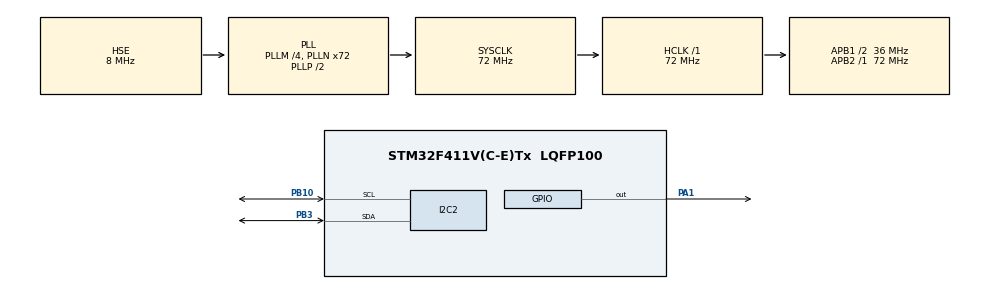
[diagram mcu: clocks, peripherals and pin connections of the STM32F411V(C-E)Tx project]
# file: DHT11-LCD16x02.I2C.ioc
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Mcu.Family=STM32F4
Mcu.Name=STM32F411V(C-E)Tx
Mcu.Package=LQFP100
NVIC.PriorityGroup=NVIC_PRIORITYGROUP_4
PA1.GPIO_PuPd=GPIO_PULLUP
PA1.Signal=GPIO_Output
PA13.Mode=Serial_Wire
PA13.Signal=SYS_JTMS-SWDIO
PA14.Mode=Serial_Wire
PA14.Signal=SYS_JTCK-SWCLK
PB10.Mode=I2C
PB10.Signal=I2C2_SCL
PB3.Mode=I2C
PB3.Signal=I2C2_SDA
PH0\ -\ OSC_IN.Mode=HSE-External-Oscillator
PH0\ -\ OSC_IN.Signal=RCC_OSC_IN
PH1\ -\ OSC_OUT.Mode=HSE-External-Oscillator
PH1\ -\ OSC_OUT.Signal=RCC_OSC_OUT
ProjectManager.HeapSize=0x200
ProjectManager.StackSize=0x400
ProjectManager.TargetToolchain=STM32CubeIDE
RCC.48MHZClocksFreq_Value=36000000
RCC.AHBFreq_Value=72000000
RCC.APB1CLKDivider=RCC_HCLK_DIV2
RCC.APB1Freq_Value=36000000
RCC.APB1TimFreq_Value=72000000
RCC.APB2Freq_Value=72000000
RCC.APB2TimFreq_Value=72000000
RCC.CortexFreq_Value=72000000
RCC.HCLKFreq_Value=72000000
RCC.HSE_VALUE=8000000
RCC.HSI_VALUE=16000000
RCC.LSE_VALUE=32768
RCC.PLLM=4
RCC.PLLN=72
RCC.PLLSourceVirtual=RCC_PLLSOURCE_HSE
RCC.SYSCLKFreq_VALUE=72000000
RCC.SYSCLKSource=RCC_SYSCLKSOURCE_PLLCLK
RCC.VCOOutputFreq_Value=144000000
TIM10.Period=0xffff-1
TIM10.Prescaler=72-1
VP_TIM10_VS_ClockSourceINT.Mode=Enable_Timer
board=custom

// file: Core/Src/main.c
/* USER CODE BEGIN Header */
/**
 ******************************************************************************
 * @file           : main.c
 * @brief          : Main program body
 ******************************************************************************
 * @attention
 *
 * Copyright (c) 2023 STMicroelectronics.
 * All rights reserved.
 *
 * This software is licensed under terms that can be found in the LICENSE file
 * in the root directory of this software component.
 * If no LICENSE file comes with this software, it is provided AS-IS.
 *
 ******************************************************************************
 */
/* USER CODE END Header */
#include "main.h"

/* USER CODE BEGIN Includes */
#include "lcd.h"
#include "stdio.h"
/* USER CODE END Includes */

/* USER CODE BEGIN PD */
#define DHT11_PORT_A GPIOA
#define DHT11_PIN_1 GPIO_PIN_1
/* USER CODE END PD */

I2C_HandleTypeDef hi2c2;

TIM_HandleTypeDef htim10;

/* USER CODE BEGIN PV */
uint8_t Rh_byte1, Rh_byte2, Temp_byte1, Temp_byte2;
uint16_t SUM, RH, TEMP;
float Temperature = 0;
float Humidity = 0;
uint8_t Presence = 0;
/* USER CODE END PV */

void SystemClock_Config(void);
static void MX_GPIO_Init(void);
static void MX_TIM10_Init(void);
static void MX_I2C2_Init(void);

/* USER CODE BEGIN 0 */
void delay_us(uint16_t us) {
	/* change your code here for the delay in microseconds */
	__HAL_TIM_SET_COUNTER(&htim10, 0);
	while ((__HAL_TIM_GET_COUNTER(&htim10)) < us)
		;
}

void Display_Temp(float Temp) {
	char str[20] = { 0 };
	lcd_put_cur(0, 7);
	sprintf(str, "%.2f", Temp);
	lcd_send_string(str);

}

void Display_Rh(float Rh) {
	char str[20] = { 0 };
	lcd_put_cur(1, 7);
	sprintf(str, "%.2f", Rh);
	lcd_send_string(str);

}

void Set_Pin_Output(GPIO_TypeDef *GPIOx, uint16_t GPIO_Pin) {
	GPIO_InitTypeDef GPIO_InitStruct = { 0 };
	GPIO_InitStruct.Pin = GPIO_Pin;
	GPIO_InitStruct.Mode = GPIO_MODE_OUTPUT_PP;
	GPIO_InitStruct.Speed = GPIO_SPEED_FREQ_LOW;
	HAL_GPIO_Init(GPIOx, &GPIO_InitStruct);
}
void Set_Pin_Input(GPIO_TypeDef *GPIOx, uint16_t GPIO_Pin) {
	GPIO_InitTypeDef GPIO_InitStruct = { 0 };
	GPIO_InitStruct.Pin = GPIO_Pin;
	GPIO_InitStruct.Mode = GPIO_MODE_INPUT;
	GPIO_InitStruct.Pull = GPIO_PULLUP;
	HAL_GPIO_Init(GPIOx, &GPIO_InitStruct);
}
void DHT11_Init() {
	Set_Pin_Output(GPIOA, GPIO_PIN_1); //set PA1 ouput to pull down in 18ms
	HAL_GPIO_WritePin(DHT11_PORT_A, DHT11_PIN_1, 0); //pull down in 18ms
	delay_us(18000); //18ms
	HAL_GPIO_WritePin(DHT11_PORT_A, DHT11_PIN_1, 1);
	delay_us(20); //pull wait
	Set_Pin_Input(DHT11_PORT_A, DHT11_PIN_1);
}
uint8_t DHT11_CheckRespone() {
	uint8_t Respone = 0;
	delay_us(40); //point middle low
	if (!HAL_GPIO_ReadPin(DHT11_PORT_A, DHT11_PIN_1)) {
		delay_us(80); //point middle high
		if (!HAL_GPIO_ReadPin(DHT11_PORT_A, DHT11_PIN_1))
			Respone = 1;
		else
			Respone = -1;
	}
		uint32_t timeout = 0;
		while (HAL_GPIO_ReadPin(DHT11_PORT_A, DHT11_PIN_1))
			if (timeout++ > 1160 * 4 * 2)
				break; //wait to go low

	return Respone;
}
uint8_t DHT11_ReadData() {

	uint8_t i, j;
	for (j = 0; j < 8; j++) {
		uint32_t timeout = 0;
		while (!(HAL_GPIO_ReadPin(DHT11_PORT_A, DHT11_PIN_1)))
			if (timeout++ > 1160 * 4 * 2)
				break; // wait for the pin to go high
		delay_us(40);   // wait for 40 us
		if (!(HAL_GPIO_ReadPin(DHT11_PORT_A, DHT11_PIN_1))) // if the pin is low
		{
			i &= ~(1 << (7 - j));   // write 0
		} else
			i |= (1 << (7 - j));  // if the pin is high, write 1
		timeout = 0;
		while ((HAL_GPIO_ReadPin(DHT11_PORT_A, DHT11_PIN_1)))
				if (timeout++ > 1160 * 4 * 2)
				break;  // wait for the pin to go low
	}

	return i;
}

/* USER CODE END 0 */

int main(void)
{

  /* MCU Configuration--------------------------------------------------------*/

  /* Reset of all peripherals, Initializes the Flash interface and the Systick. */
  HAL_Init();

  /* Configure the system clock */
  SystemClock_Config();

  /* Initialize all configured peripherals */
  MX_GPIO_Init();
  MX_TIM10_Init();
  MX_I2C2_Init();
  /* USER CODE BEGIN 2 */
	HAL_TIM_Base_Start(&htim10);

	lcd_init(); //  lcd init phải dặt sau i2c init nha

	lcd_clear();
	lcd_send_string("TEMP :         C");
	lcd_put_cur(1, 0);
	lcd_send_string("RH   :        %");
	lcd_put_cur(0, 14);
	lcd_send_data(0b11011111);
  /* USER CODE END 2 */

  /* Infinite loop */
  /* USER CODE BEGIN WHILE */
	while (1) {
		Display_Temp(Temperature);
		Display_Rh(Humidity);
		DHT11_Init();
		Presence = DHT11_CheckRespone();
		Rh_byte1 = DHT11_ReadData();
		Rh_byte2 = DHT11_ReadData();
		Temp_byte1 = DHT11_ReadData();
		Temp_byte2 = DHT11_ReadData();
		SUM = DHT11_ReadData();
		TEMP = Temp_byte1;
		RH = Rh_byte1;

		Temperature = (float)((float)TEMP+((float)Temp_byte2/10));
		Humidity = (float)((float)RH+((float)Rh_byte2/10));

		HAL_Delay(1000);
    /* USER CODE END WHILE */

	}
}

void SystemClock_Config(void)
{
  RCC_OscInitTypeDef RCC_OscInitStruct = {0};
  RCC_ClkInitTypeDef RCC_ClkInitStruct = {0};

  /** Configure the main internal regulator output voltage
  */
  __HAL_RCC_PWR_CLK_ENABLE();
  __HAL_PWR_VOLTAGESCALING_CONFIG(PWR_REGULATOR_VOLTAGE_SCALE1);

  /** Initializes the RCC Oscillators according to the specified parameters
  * in the RCC_OscInitTypeDef structure.
  */
  RCC_OscInitStruct.OscillatorType = RCC_OSCILLATORTYPE_HSE;
  RCC_OscInitStruct.HSEState = RCC_HSE_ON;
  RCC_OscInitStruct.PLL.PLLState = RCC_PLL_ON;
  RCC_OscInitStruct.PLL.PLLSource = RCC_PLLSOURCE_HSE;
  RCC_OscInitStruct.PLL.PLLM = 4;
  RCC_OscInitStruct.PLL.PLLN = 72;
  RCC_OscInitStruct.PLL.PLLP = RCC_PLLP_DIV2;
  RCC_OscInitStruct.PLL.PLLQ = 4;
  if (HAL_RCC_OscConfig(&RCC_OscInitStruct) != HAL_OK)
  {
    Error_Handler();
  }

  /** Initializes the CPU, AHB and APB buses clocks
  */
  RCC_ClkInitStruct.ClockType = RCC_CLOCKTYPE_HCLK|RCC_CLOCKTYPE_SYSCLK
                              |RCC_CLOCKTYPE_PCLK1|RCC_CLOCKTYPE_PCLK2;
  RCC_ClkInitStruct.SYSCLKSource = RCC_SYSCLKSOURCE_PLLCLK;
  RCC_ClkInitStruct.AHBCLKDivider = RCC_SYSCLK_DIV1;
  RCC_ClkInitStruct.APB1CLKDivider = RCC_HCLK_DIV2;
  RCC_ClkInitStruct.APB2CLKDivider = RCC_HCLK_DIV1;

  if (HAL_RCC_ClockConfig(&RCC_ClkInitStruct, FLASH_LATENCY_2) != HAL_OK)
  {
    Error_Handler();
  }
}

static void MX_I2C2_Init(void)
{

  hi2c2.Instance = I2C2;
  hi2c2.Init.ClockSpeed = 100000;
  hi2c2.Init.DutyCycle = I2C_DUTYCYCLE_2;
  hi2c2.Init.OwnAddress1 = 0;
  hi2c2.Init.AddressingMode = I2C_ADDRESSINGMODE_7BIT;
  hi2c2.Init.DualAddressMode = I2C_DUALADDRESS_DISABLE;
  hi2c2.Init.OwnAddress2 = 0;
  hi2c2.Init.GeneralCallMode = I2C_GENERALCALL_DISABLE;
  hi2c2.Init.NoStretchMode = I2C_NOSTRETCH_DISABLE;
  if (HAL_I2C_Init(&hi2c2) != HAL_OK)
  {
    Error_Handler();
  }

}

static void MX_TIM10_Init(void)
{

  htim10.Instance = TIM10;
  htim10.Init.Prescaler = 72-1;
  htim10.Init.CounterMode = TIM_COUNTERMODE_UP;
  htim10.Init.Period = 0xffff-1;
  htim10.Init.ClockDivision = TIM_CLOCKDIVISION_DIV1;
  htim10.Init.AutoReloadPreload = TIM_AUTORELOAD_PRELOAD_DISABLE;
  if (HAL_TIM_Base_Init(&htim10) != HAL_OK)
  {
    Error_Handler();
  }

}

static void MX_GPIO_Init(void)
{
  GPIO_InitTypeDef GPIO_InitStruct = {0};

  /* GPIO Ports Clock Enable */
  __HAL_RCC_GPIOH_CLK_ENABLE();
  __HAL_RCC_GPIOA_CLK_ENABLE();
  __HAL_RCC_GPIOB_CLK_ENABLE();

  /*Configure GPIO pin Output Level */
  HAL_GPIO_WritePin(GPIOA, GPIO_PIN_1, GPIO_PIN_RESET);

  /*Configure GPIO pin : PA1 */
  GPIO_InitStruct.Pin = GPIO_PIN_1;
  GPIO_InitStruct.Mode = GPIO_MODE_OUTPUT_PP;
  GPIO_InitStruct.Pull = GPIO_PULLUP;
  GPIO_InitStruct.Speed = GPIO_SPEED_FREQ_LOW;
  HAL_GPIO_Init(GPIOA, &GPIO_InitStruct);

}

void Error_Handler(void)
{
	__disable_irq();
	while (1) {
	}
}
